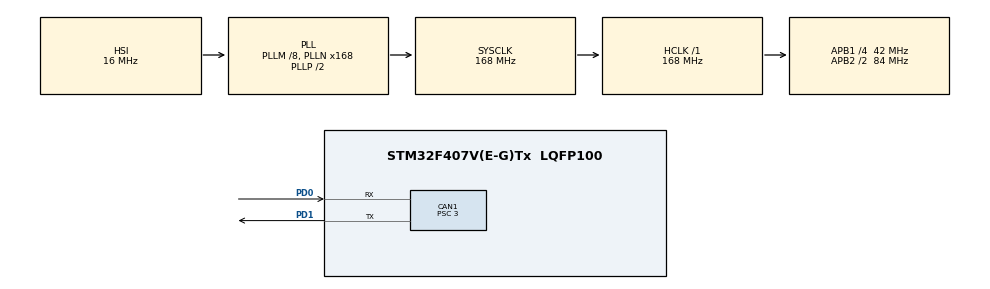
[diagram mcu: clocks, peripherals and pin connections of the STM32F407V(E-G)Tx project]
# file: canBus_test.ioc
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CAN1.BS1=CAN_BS1_11TQ
CAN1.BS2=CAN_BS2_2TQ
CAN1.CalculateBaudRate=1000000
CAN1.CalculateTimeBit=1000
CAN1.CalculateTimeQuantum=71.42857142857143
CAN1.NART=ENABLE
CAN1.Prescaler=3
CAN1.TXFP=DISABLE
Mcu.Family=STM32F4
Mcu.Name=STM32F407V(E-G)Tx
Mcu.Package=LQFP100
NVIC.CAN1_TX_IRQn=true\:0\:0\:false\:false\:true\:true\:true\:true
NVIC.PriorityGroup=NVIC_PRIORITYGROUP_4
PA13.Mode=Serial_Wire
PA13.Signal=SYS_JTMS-SWDIO
PA14.Mode=Serial_Wire
PA14.Signal=SYS_JTCK-SWCLK
PC14-OSC32_IN.Mode=LSE-External-Oscillator
PC14-OSC32_IN.Signal=RCC_OSC32_IN
PC15-OSC32_OUT.Mode=LSE-External-Oscillator
PC15-OSC32_OUT.Signal=RCC_OSC32_OUT
PD0.Mode=CAN_Activate
PD0.Signal=CAN1_RX
PD1.Mode=CAN_Activate
PD1.Signal=CAN1_TX
PH0-OSC_IN.Mode=HSE-External-Clock-Source
PH0-OSC_IN.Signal=RCC_OSC_IN
PH1-OSC_OUT.Mode=HSE-External-Clock-Source
PH1-OSC_OUT.Signal=RCC_OSC_OUT
ProjectManager.HeapSize=0x200
ProjectManager.StackSize=0x400
ProjectManager.TargetToolchain=STM32CubeIDE
RCC.48MHZClocksFreq_Value=84000000
RCC.AHBFreq_Value=168000000
RCC.APB1CLKDivider=RCC_HCLK_DIV4
RCC.APB1Freq_Value=42000000
RCC.APB1TimFreq_Value=84000000
RCC.APB2CLKDivider=RCC_HCLK_DIV2
RCC.APB2Freq_Value=84000000
RCC.APB2TimFreq_Value=168000000
RCC.CortexFreq_Value=168000000
RCC.HCLKFreq_Value=168000000
RCC.HSE_VALUE=25000000
RCC.HSI_VALUE=16000000
RCC.PLLM=8
RCC.PLLN=168
RCC.SYSCLKFreq_VALUE=168000000
RCC.SYSCLKSource=RCC_SYSCLKSOURCE_PLLCLK
RCC.VCOOutputFreq_Value=336000000
board=custom

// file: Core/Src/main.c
/* USER CODE BEGIN Header */
/**
 ******************************************************************************
 * @file           : main.c
 * @brief          : Main program body
 ******************************************************************************
 * @attention
 *
 * Copyright (c) 2024 STMicroelectronics.
 * All rights reserved.
 *
 * This software is licensed under terms that can be found in the LICENSE file
 * in the root directory of this software component.
 * If no LICENSE file comes with this software, it is provided AS-IS.
 *
 ******************************************************************************
 */
/* USER CODE END Header */
#include "main.h"

/* USER CODE BEGIN Includes */
#include "stdbool.h"
#include "stdio.h"
#include "string.h"
/* USER CODE END Includes */

/* USER CODE BEGIN PTD */
typedef struct {
	float tf;
	int16_t value;
	bool status;
} myData;
/* USER CODE END PTD */

CAN_HandleTypeDef hcan1;

/* USER CODE BEGIN PV */
CAN_TxHeaderTypeDef txHead;
CAN_RxHeaderTypeDef rxHead;
CAN_FilterTypeDef canFil;

myData dat;
uint8_t txData[8];
int16_t kirim[4], terima[4];
uint32_t txMailbox;
/* USER CODE END PV */

void SystemClock_Config(void);
static void MX_GPIO_Init(void);
static void MX_CAN1_Init(void);

int main(void)
{

  /* MCU Configuration--------------------------------------------------------*/

  /* Reset of all peripherals, Initializes the Flash interface and the Systick. */
  HAL_Init();

  /* Configure the system clock */
  SystemClock_Config();

  /* Initialize all configured peripherals */
  MX_GPIO_Init();
  MX_CAN1_Init();
  /* USER CODE BEGIN 2 */
	txHead.IDE = CAN_ID_STD;
	txHead.StdId = 0x123;
	txHead.ExtId = 0x124;
	txHead.RTR = CAN_RTR_DATA;
	txHead.DLC = 8;

	canFil.FilterActivation = CAN_FILTER_ENABLE;
	canFil.FilterBank = 0; // which filter bank to use from the assigned ones
	canFil.FilterFIFOAssignment = CAN_FILTER_FIFO0;
	canFil.FilterIdHigh = 0;
	canFil.FilterIdLow = 0;
	canFil.FilterMaskIdHigh = 0;
	canFil.FilterMaskIdLow = 0;
	canFil.FilterMode = CAN_FILTERMODE_IDMASK;
	canFil.FilterScale = CAN_FILTERSCALE_32BIT;
	canFil.SlaveStartFilterBank = 14;

	HAL_CAN_ConfigFilter(&hcan1, &canFil);
	HAL_CAN_Start(&hcan1);
	HAL_CAN_ActivateNotification(&hcan1, CAN_RX_FIFO0);
	kirim[0] = -200;
	kirim[1] = 200;
	kirim[2] = -600;
	kirim[3] = 600;
  /* USER CODE END 2 */

  /* Infinite loop */
	while (1) {

    /* USER CODE BEGIN 3 */
		HAL_CAN_AddTxMessage(&hcan1, &txHead, (uint8_t*)kirim, &txMailbox);
		HAL_CAN_GetRxMessage(&hcan1, CAN_RX_FIFO0, &rxHead, (uint8_t*)terima);
		HAL_Delay(10);
	}
  /* USER CODE END 3 */
}

void SystemClock_Config(void)
{
  RCC_OscInitTypeDef RCC_OscInitStruct = {0};
  RCC_ClkInitTypeDef RCC_ClkInitStruct = {0};

  /** Configure the main internal regulator output voltage
  */
  __HAL_RCC_PWR_CLK_ENABLE();
  __HAL_PWR_VOLTAGESCALING_CONFIG(PWR_REGULATOR_VOLTAGE_SCALE1);

  /** Initializes the RCC Oscillators according to the specified parameters
  * in the RCC_OscInitTypeDef structure.
  */
  RCC_OscInitStruct.OscillatorType = RCC_OSCILLATORTYPE_HSI;
  RCC_OscInitStruct.HSIState = RCC_HSI_ON;
  RCC_OscInitStruct.HSICalibrationValue = RCC_HSICALIBRATION_DEFAULT;
  RCC_OscInitStruct.PLL.PLLState = RCC_PLL_ON;
  RCC_OscInitStruct.PLL.PLLSource = RCC_PLLSOURCE_HSI;
  RCC_OscInitStruct.PLL.PLLM = 8;
  RCC_OscInitStruct.PLL.PLLN = 168;
  RCC_OscInitStruct.PLL.PLLP = RCC_PLLP_DIV2;
  RCC_OscInitStruct.PLL.PLLQ = 4;
  if (HAL_RCC_OscConfig(&RCC_OscInitStruct) != HAL_OK)
  {
    Error_Handler();
  }

  /** Initializes the CPU, AHB and APB buses clocks
  */
  RCC_ClkInitStruct.ClockType = RCC_CLOCKTYPE_HCLK|RCC_CLOCKTYPE_SYSCLK
                              |RCC_CLOCKTYPE_PCLK1|RCC_CLOCKTYPE_PCLK2;
  RCC_ClkInitStruct.SYSCLKSource = RCC_SYSCLKSOURCE_PLLCLK;
  RCC_ClkInitStruct.AHBCLKDivider = RCC_SYSCLK_DIV1;
  RCC_ClkInitStruct.APB1CLKDivider = RCC_HCLK_DIV4;
  RCC_ClkInitStruct.APB2CLKDivider = RCC_HCLK_DIV2;

  if (HAL_RCC_ClockConfig(&RCC_ClkInitStruct, FLASH_LATENCY_5) != HAL_OK)
  {
    Error_Handler();
  }
}

static void MX_CAN1_Init(void)
{

  hcan1.Instance = CAN1;
  hcan1.Init.Prescaler = 3;
  hcan1.Init.Mode = CAN_MODE_NORMAL;
  hcan1.Init.SyncJumpWidth = CAN_SJW_1TQ;
  hcan1.Init.TimeSeg1 = CAN_BS1_11TQ;
  hcan1.Init.TimeSeg2 = CAN_BS2_2TQ;
  hcan1.Init.TimeTriggeredMode = DISABLE;
  hcan1.Init.AutoBusOff = DISABLE;
  hcan1.Init.AutoWakeUp = DISABLE;
  hcan1.Init.AutoRetransmission = ENABLE;
  hcan1.Init.ReceiveFifoLocked = DISABLE;
  hcan1.Init.TransmitFifoPriority = DISABLE;
  if (HAL_CAN_Init(&hcan1) != HAL_OK)
  {
    Error_Handler();
  }

}

static void MX_GPIO_Init(void)
{

  /* GPIO Ports Clock Enable */
  __HAL_RCC_GPIOC_CLK_ENABLE();
  __HAL_RCC_GPIOH_CLK_ENABLE();
  __HAL_RCC_GPIOA_CLK_ENABLE();
  __HAL_RCC_GPIOD_CLK_ENABLE();

}

void Error_Handler(void)
{
	__disable_irq();
	while (1) {
	}
}
